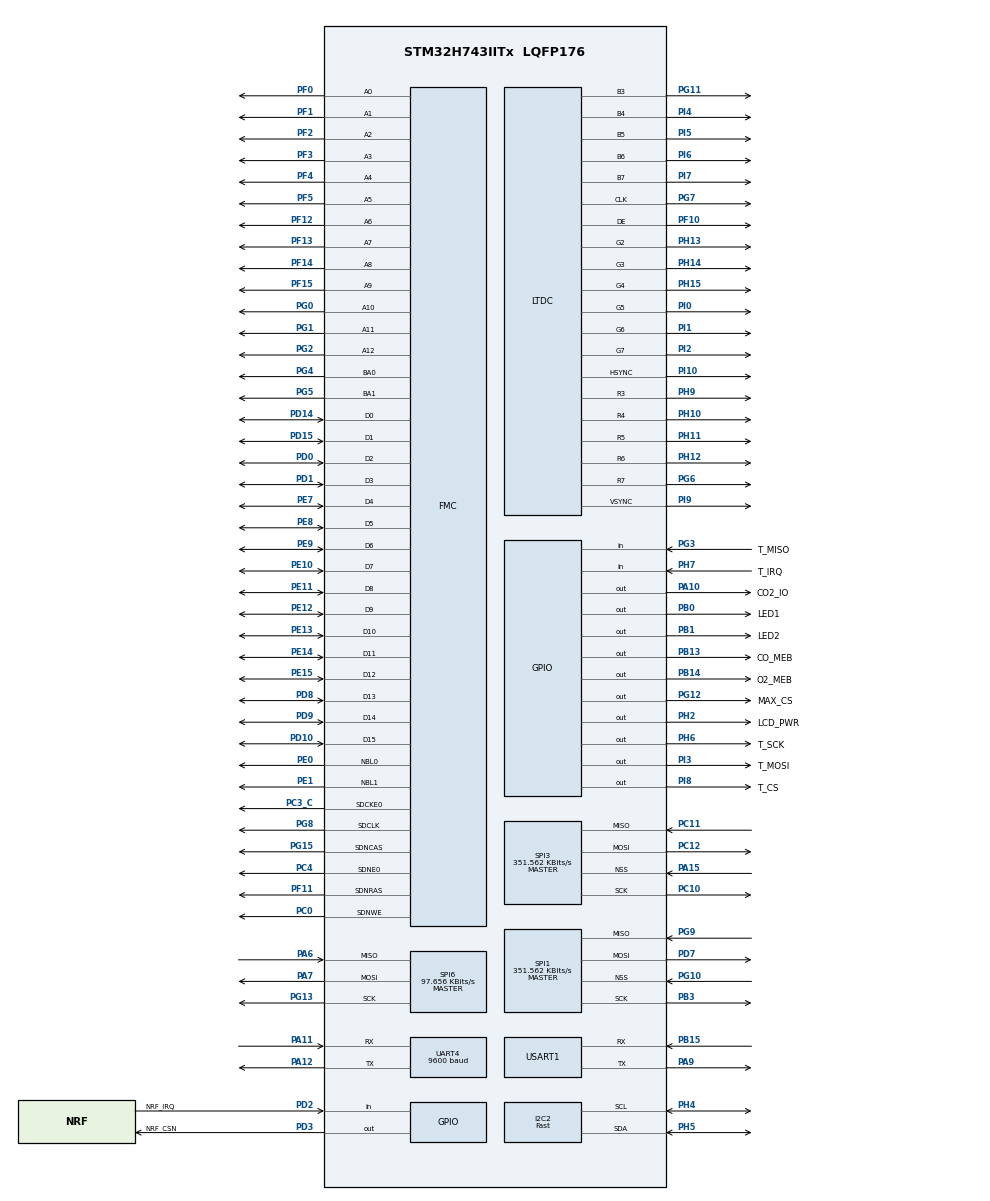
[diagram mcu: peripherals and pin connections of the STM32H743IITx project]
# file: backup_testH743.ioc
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CORTEX_M7.AccessPermission_Spec=MPU_REGION_FULL_ACCESS
CORTEX_M7.BaseAddress_Spec=0x24000000
CORTEX_M7.CPU_DCache=Enabled
CORTEX_M7.CPU_ICache=Enabled
CORTEX_M7.IsBufferable_Spec=MPU_ACCESS_BUFFERABLE
CORTEX_M7.IsCacheable_Spec=MPU_ACCESS_CACHEABLE
CORTEX_M7.IsShareable_Spec=MPU_ACCESS_NOT_SHAREABLE
CORTEX_M7.MPU_Control=MPU_PRIVILEGED_DEFAULT
CORTEX_M7.Size_Spec=MPU_REGION_SIZE_512KB
CORTEX_M7.SubRegionDisable_Spec=0x0
CORTEX_M7.default_mode_Activation=1
DMA2D.ColorMode=DMA2D_OUTPUT_RGB565
Dma.I2C2_RX.0.Direction=DMA_PERIPH_TO_MEMORY
Dma.I2C2_RX.0.EventEnable=DISABLE
Dma.I2C2_RX.0.FIFOMode=DMA_FIFOMODE_DISABLE
Dma.I2C2_RX.0.Instance=DMA1_Stream0
Dma.I2C2_RX.0.MemDataAlignment=DMA_MDATAALIGN_BYTE
Dma.I2C2_RX.0.MemInc=DMA_MINC_ENABLE
Dma.I2C2_RX.0.Mode=DMA_NORMAL
Dma.I2C2_RX.0.PeriphDataAlignment=DMA_PDATAALIGN_BYTE
Dma.I2C2_RX.0.PeriphInc=DMA_PINC_DISABLE
Dma.I2C2_RX.0.Polarity=HAL_DMAMUX_REQ_GEN_RISING
Dma.I2C2_RX.0.Priority=DMA_PRIORITY_LOW
Dma.I2C2_RX.0.RequestNumber=1
Dma.I2C2_RX.0.SignalID=NONE
Dma.I2C2_RX.0.SyncEnable=DISABLE
Dma.I2C2_RX.0.SyncPolarity=HAL_DMAMUX_SYNC_NO_EVENT
Dma.I2C2_RX.0.SyncRequestNumber=1
Dma.I2C2_RX.0.SyncSignalID=NONE
Dma.Request0=I2C2_RX
Dma.Request1=UART4_RX
Dma.UART4_RX.1.Direction=DMA_PERIPH_TO_MEMORY
Dma.UART4_RX.1.EventEnable=DISABLE
Dma.UART4_RX.1.FIFOMode=DMA_FIFOMODE_DISABLE
Dma.UART4_RX.1.Instance=DMA1_Stream1
Dma.UART4_RX.1.MemDataAlignment=DMA_MDATAALIGN_BYTE
Dma.UART4_RX.1.MemInc=DMA_MINC_ENABLE
Dma.UART4_RX.1.Mode=DMA_NORMAL
Dma.UART4_RX.1.PeriphDataAlignment=DMA_PDATAALIGN_BYTE
Dma.UART4_RX.1.PeriphInc=DMA_PINC_DISABLE
Dma.UART4_RX.1.Polarity=HAL_DMAMUX_REQ_GEN_RISING
Dma.UART4_RX.1.Priority=DMA_PRIORITY_LOW
Dma.UART4_RX.1.RequestNumber=1
Dma.UART4_RX.1.SignalID=NONE
Dma.UART4_RX.1.SyncEnable=DISABLE
Dma.UART4_RX.1.SyncPolarity=HAL_DMAMUX_SYNC_NO_EVENT
Dma.UART4_RX.1.SyncRequestNumber=1
Dma.UART4_RX.1.SyncSignalID=NONE
FMC.CASLatency1=FMC_SDRAM_CAS_LATENCY_3
FMC.ColumnBitsNumber1=FMC_SDRAM_COLUMN_BITS_NUM_9
FMC.ExitSelfRefreshDelay1=7
FMC.LoadToActiveDelay1=2
FMC.RCDDelay1=2
FMC.RPDelay1=2
FMC.RPDelay2=2
FMC.ReadBurst1=FMC_SDRAM_RBURST_ENABLE
FMC.ReadBurst2=FMC_SDRAM_RBURST_ENABLE
FMC.ReadPipeDelay1=FMC_SDRAM_RPIPE_DELAY_1
FMC.ReadPipeDelay2=FMC_SDRAM_RPIPE_DELAY_1
FMC.RowCycleDelay1=7
FMC.RowCycleDelay2=7
FMC.SDClockPeriod1=FMC_SDRAM_CLOCK_PERIOD_2
FMC.SDClockPeriod2=FMC_SDRAM_CLOCK_PERIOD_2
FMC.SelfRefreshTime1=5
FMC.WriteRecoveryTime1=4
FREERTOS.Mutexes01=sensorDataMutex,Dynamic,NULL,Available
FREERTOS.Tasks01=ControlTask,24,512,StartControlTask,Default,NULL,Dynamic,NULL,NULL;GUI_Task,40,8192,TouchGFX_Task,As external,NULL,Dynamic,NULL,NULL;SensorTask_I2C,24,512,StartSensorTask_I2C,Default,NULL,Dynamic,NULL,NULL;SensorTask_UART,24,512,StartSensorTask_UART,Default,NULL,Dynamic,NULL,NULL;SensorTask_SPI,24,512,StartSensorTask_SPI,Default,NULL,Dynamic,NULL,NULL;CommTask_NRT_SD,8,1536,StartCommTask_NRF_SD,Default,NULL,Dynamic,NULL,NULL
FREERTOS.configENABLE_FPU=1
FREERTOS.configTOTAL_HEAP_SIZE=65536
FREERTOS.configUSE_NEWLIB_REENTRANT=1
I2C2.I2C_Speed_Mode=I2C_Fast
I2C2.Timing=0x009034B6
LTDC.ActiveH=272
LTDC.ActiveW=480
LTDC.Alpha0_L0=0
LTDC.Alpha_L0=255
LTDC.FBStartAdress_L0=0xC0000000
LTDC.HBP=2
LTDC.HFP=2
LTDC.HSync=41
LTDC.ImageHeight_L0=272
LTDC.ImageWidth_L0=480
LTDC.Layers=0
LTDC.PixelFormat_L0=LTDC_PIXEL_FORMAT_RGB565
LTDC.VBP=2
LTDC.VFP=2
LTDC.VSync=10
LTDC.WindowX1_L0=480
LTDC.WindowY1_L0=272
Mcu.Family=STM32H7
Mcu.Name=STM32H743IITx
Mcu.Package=LQFP176
NVIC.DMA1_Stream0_IRQn=true\:5\:0\:false\:false\:true\:true\:false\:true\:true
NVIC.DMA1_Stream1_IRQn=true\:5\:0\:false\:false\:true\:true\:false\:true\:true
NVIC.DMA2D_IRQn=true\:6\:0\:true\:false\:true\:true\:true\:true\:true
NVIC.LTDC_ER_IRQn=true\:6\:0\:true\:false\:true\:true\:true\:true\:true
NVIC.LTDC_IRQn=true\:6\:0\:true\:false\:true\:true\:true\:true\:true
NVIC.PriorityGroup=NVIC_PRIORITYGROUP_4
NVIC.TIM6_DAC_IRQn=true\:15\:0\:false\:false\:true\:false\:false\:true\:true
NVIC.TimeBase=TIM6_DAC_IRQn
NVIC.TimeBaseIP=TIM6
PA10.GPIO_Label=CO2_IO
PA10.PinState=GPIO_PIN_SET
PA10.Signal=GPIO_Output
PA11.Mode=Asynchronous
PA11.Signal=UART4_RX
PA12.Mode=Asynchronous
PA12.Signal=UART4_TX
PA13\ (JTMS/SWDIO).Mode=Serial_Wire
PA13\ (JTMS/SWDIO).Signal=DEBUG_JTMS-SWDIO
PA14\ (JTCK/SWCLK).Mode=Serial_Wire
PA14\ (JTCK/SWCLK).Signal=DEBUG_JTCK-SWCLK
PA15\ (JTDI).Mode=NSS_Signal_Hard_Input
PA15\ (JTDI).Signal=SPI3_NSS
PA6.Mode=Full_Duplex_Master
PA6.Signal=SPI6_MISO
PA7.Mode=Full_Duplex_Master
PA7.Signal=SPI6_MOSI
PA9.Mode=Asynchronous
PA9.Signal=USART1_TX
PB0.GPIO_Label=LED1
PB0.Signal=GPIO_Output
PB1.GPIO_Label=LED2
PB1.Signal=GPIO_Output
PB13.GPIO_Label=CO_MEB
PB13.PinState=GPIO_PIN_SET
PB13.Signal=GPIO_Output
PB14.GPIO_Label=O2_MEB
PB14.PinState=GPIO_PIN_SET
PB14.Signal=GPIO_Output
PB15.Mode=Asynchronous
PB15.Signal=USART1_RX
PB3\ (JTDO/TRACESWO).Mode=Full_Duplex_Master
PB3\ (JTDO/TRACESWO).Signal=SPI1_SCK
PC0.Signal=FMC_SDNWE
PC10.Mode=Full_Duplex_Master
PC10.Signal=SPI3_SCK
PC11.Mode=Full_Duplex_Master
PC11.Signal=SPI3_MISO
PC12.Mode=Full_Duplex_Master
PC12.Signal=SPI3_MOSI
PC14-OSC32_IN\ (OSC32_IN).Mode=LSE-External-Oscillator
PC14-OSC32_IN\ (OSC32_IN).Signal=RCC_OSC32_IN
PC15-OSC32_OUT\ (OSC32_OUT).Mode=LSE-External-Oscillator
PC15-OSC32_OUT\ (OSC32_OUT).Signal=RCC_OSC32_OUT
PC3_C.Mode=SdramChipSelect1_1
PC3_C.Signal=FMC_SDCKE0
PC4.Mode=SdramChipSelect1_1
PC4.Signal=FMC_SDNE0
PD0.Signal=FMC_D2_DA2
PD1.Signal=FMC_D3_DA3
PD10.Signal=FMC_D15_DA15
PD14.Signal=FMC_D0_DA0
PD15.Signal=FMC_D1_DA1
PD2.GPIO_Label=NRF_IRQ
PD2.Signal=GPIO_Input
PD3.GPIO_Label=NRF_CSN
PD3.Signal=GPIO_Output
PD7.Mode=Full_Duplex_Master
PD7.Signal=SPI1_MOSI
PD8.Signal=FMC_D13_DA13
PD9.Signal=FMC_D14_DA14
PE0.Signal=FMC_NBL0
PE1.Signal=FMC_NBL1
PE10.Signal=FMC_D7_DA7
PE11.Signal=FMC_D8_DA8
PE12.Signal=FMC_D9_DA9
PE13.Signal=FMC_D10_DA10
PE14.Signal=FMC_D11_DA11
PE15.Signal=FMC_D12_DA12
PE7.Signal=FMC_D4_DA4
PE8.Signal=FMC_D5_DA5
PE9.Signal=FMC_D6_DA6
PF0.Signal=FMC_A0
PF1.Signal=FMC_A1
PF10.Mode=RGB565
PF10.Signal=LTDC_DE
PF11.Signal=FMC_SDNRAS
PF12.Signal=FMC_A6
PF13.Signal=FMC_A7
PF14.Signal=FMC_A8
PF15.Signal=FMC_A9
PF2.Signal=FMC_A2
PF3.Signal=FMC_A3
PF4.Signal=FMC_A4
PF5.Signal=FMC_A5
PG0.Signal=FMC_A10
PG1.Signal=FMC_A11
PG10.Mode=NSS_Signal_Hard_Input
PG10.Signal=SPI1_NSS
PG11.Mode=RGB565
PG11.Signal=LTDC_B3
PG12.GPIO_Label=MAX_CS
PG12.Signal=GPIO_Output
PG13.Mode=Full_Duplex_Master
PG13.Signal=SPI6_SCK
PG15.Signal=FMC_SDNCAS
PG2.Signal=FMC_A12
PG3.GPIO_Label=T_MISO
PG3.Signal=GPIO_Input
PG4.Signal=FMC_A14_BA0
PG5.Signal=FMC_A15_BA1
PG6.Mode=RGB565
PG6.Signal=LTDC_R7
PG7.Mode=RGB565
PG7.Signal=LTDC_CLK
PG8.Signal=FMC_SDCLK
PG9.Mode=Full_Duplex_Master
PG9.Signal=SPI1_MISO
PH0-OSC_IN\ (PH0).Mode=HSE-External-Oscillator
PH0-OSC_IN\ (PH0).Signal=RCC_OSC_IN
PH1-OSC_OUT\ (PH1).Mode=HSE-External-Oscillator
PH1-OSC_OUT\ (PH1).Signal=RCC_OSC_OUT
PH10.Mode=RGB565
PH10.Signal=LTDC_R4
PH11.Mode=RGB565
PH11.Signal=LTDC_R5
PH12.Mode=RGB565
PH12.Signal=LTDC_R6
PH13.Mode=RGB565
PH13.Signal=LTDC_G2
PH14.Mode=RGB565
PH14.Signal=LTDC_G3
PH15.Mode=RGB565
PH15.Signal=LTDC_G4
PH2.GPIO_Label=LCD_PWR
PH2.PinState=GPIO_PIN_SET
PH2.Signal=GPIO_Output
PH4.Mode=I2C
PH4.Signal=I2C2_SCL
PH5.Mode=I2C
PH5.Signal=I2C2_SDA
PH6.GPIO_Label=T_SCK
PH6.Signal=GPIO_Output
PH7.GPIO_Label=T_IRQ
PH7.GPIO_PuPd=GPIO_NOPULL
PH7.Signal=GPIO_Input
PH9.Mode=RGB565
PH9.Signal=LTDC_R3
PI0.Mode=RGB565
PI0.Signal=LTDC_G5
PI1.Mode=RGB565
PI1.Signal=LTDC_G6
PI10.Mode=RGB565
PI10.Signal=LTDC_HSYNC
PI2.Mode=RGB565
PI2.Signal=LTDC_G7
PI3.GPIO_Label=T_MOSI
PI3.Signal=GPIO_Output
PI4.Mode=RGB565
PI4.Signal=LTDC_B4
PI5.Mode=RGB565
PI5.Signal=LTDC_B5
PI6.Mode=RGB565
PI6.Signal=LTDC_B6
PI7.Mode=RGB565
PI7.Signal=LTDC_B7
PI8.GPIO_Label=T_CS
PI8.Signal=GPIO_Output
PI9.Mode=RGB565
PI9.Signal=LTDC_VSYNC
ProjectManager.HeapSize=0x1000
ProjectManager.StackSize=0x1000
ProjectManager.TargetToolchain=STM32CubeIDE
RCC.ADCCLockSelection=RCC_ADCCLKSOURCE_CLKP
RCC.ADCFreq_Value=64000000
RCC.APB1Freq_Value=100000000
RCC.APB2Freq_Value=100000000
RCC.APB3Freq_Value=100000000
RCC.APB4Freq_Value=100000000
RCC.CortexFreq_Value=400000000
RCC.D1PPRE=RCC_APB3_DIV2
RCC.D2PPRE1=RCC_APB1_DIV2
RCC.D2PPRE2=RCC_APB2_DIV2
RCC.D3PPRE=RCC_APB4_DIV2
RCC.DIVM1=2
RCC.DIVM2=25
RCC.DIVM3=5
RCC.DIVN1=64
RCC.DIVN2=360
RCC.DIVN3=36
RCC.DIVR2=3
RCC.DIVR3=20
RCC.FMCCLockSelection=RCC_FMCCLKSOURCE_PLL2
RCC.HCLKFreq_Value=200000000
RCC.HPRE=RCC_HCLK_DIV2
RCC.LockedElements=D1CPREOutput,AHBOutput,LTDCOutput,FMCoutput,CpuClockOutput,CortexSysOutput
RCC.PLL2FRACN=0
RCC.PLL3FRACN=0
RCC.PLLFRACN=0
RCC.PLLSourceVirtual=RCC_PLLSOURCE_HSE
RCC.PWR_Regulator_Voltage_Scale=PWR_REGULATOR_VOLTAGE_SCALE0
RCC.SPI123CLockSelection=RCC_SPI123CLKSOURCE_PLL3
RCC.SPI6CLockSelection=RCC_SPI6CLKSOURCE_HSE
RCC.SYSCLKFreq_VALUE=400000000
RCC.SYSCLKSource=RCC_SYSCLKSOURCE_PLLCLK
RCC.USBFreq_Value=400000000
RTC.Month=RTC_MONTH_APRIL
RTC.WeekDay=RTC_WEEKDAY_SATURDAY
SH.FMC_A0.0=FMC_A0,13b-sda1
SH.FMC_A1.0=FMC_A1,13b-sda1
SH.FMC_A10.0=FMC_A10,13b-sda1
SH.FMC_A11.0=FMC_A11,13b-sda1
SH.FMC_A12.0=FMC_A12,13b-sda1
SH.FMC_A14_BA0.0=FMC_BA0,FourSdramBanks1
SH.FMC_A15_BA1.0=FMC_BA1,FourSdramBanks1
SH.FMC_A2.0=FMC_A2,13b-sda1
SH.FMC_A3.0=FMC_A3,13b-sda1
SH.FMC_A4.0=FMC_A4,13b-sda1
SH.FMC_A5.0=FMC_A5,13b-sda1
SH.FMC_A6.0=FMC_A6,13b-sda1
SH.FMC_A7.0=FMC_A7,13b-sda1
SH.FMC_A8.0=FMC_A8,13b-sda1
SH.FMC_A9.0=FMC_A9,13b-sda1
SH.FMC_D0_DA0.0=FMC_D0,sd-16b-d1
SH.FMC_D10_DA10.0=FMC_D10,sd-16b-d1
SH.FMC_D11_DA11.0=FMC_D11,sd-16b-d1
SH.FMC_D12_DA12.0=FMC_D12,sd-16b-d1
SH.FMC_D13_DA13.0=FMC_D13,sd-16b-d1
SH.FMC_D14_DA14.0=FMC_D14,sd-16b-d1
SH.FMC_D15_DA15.0=FMC_D15,sd-16b-d1
SH.FMC_D1_DA1.0=FMC_D1,sd-16b-d1
SH.FMC_D2_DA2.0=FMC_D2,sd-16b-d1
SH.FMC_D3_DA3.0=FMC_D3,sd-16b-d1
SH.FMC_D4_DA4.0=FMC_D4,sd-16b-d1
SH.FMC_D5_DA5.0=FMC_D5,sd-16b-d1
SH.FMC_D6_DA6.0=FMC_D6,sd-16b-d1
SH.FMC_D7_DA7.0=FMC_D7,sd-16b-d1
SH.FMC_D8_DA8.0=FMC_D8,sd-16b-d1
SH.FMC_D9_DA9.0=FMC_D9,sd-16b-d1
SH.FMC_NBL0.0=FMC_NBL0,Sd2ByteEnable1
SH.FMC_NBL1.0=FMC_NBL1,Sd2ByteEnable1
SH.FMC_SDCLK.0=FMC_SDCLK,13b-sda1
SH.FMC_SDNCAS.0=FMC_SDNCAS,13b-sda1
SH.FMC_SDNRAS.0=FMC_SDNRAS,13b-sda1
SH.FMC_SDNWE.0=FMC_SDNWE,13b-sda1
SPI1.BaudRatePrescaler=SPI_BAUDRATEPRESCALER_256
SPI1.CalculateBaudRate=351.562 KBits/s
SPI1.Direction=SPI_DIRECTION_2LINES
SPI1.Mode=SPI_MODE_MASTER
SPI1.VirtualNSS=VM_NSSHARD
SPI1.VirtualType=VM_MASTER
SPI3.BaudRatePrescaler=SPI_BAUDRATEPRESCALER_256
SPI3.CalculateBaudRate=351.562 KBits/s
SPI3.Direction=SPI_DIRECTION_2LINES
SPI3.Mode=SPI_MODE_MASTER
SPI3.VirtualNSS=VM_NSSHARD
SPI3.VirtualType=VM_MASTER
SPI6.BaudRatePrescaler=SPI_BAUDRATEPRESCALER_256
SPI6.CalculateBaudRate=97.656 KBits/s
SPI6.Direction=SPI_DIRECTION_2LINES
SPI6.Mode=SPI_MODE_MASTER
SPI6.VirtualType=VM_MASTER
STMicroelectronics.X-CUBE-TOUCHGFX.4.26.0.ApplicationCcGraphicsJjApplication=TouchGFXOoGenerator
STMicroelectronics.X-CUBE-TOUCHGFX.4.26.0.tgfx_address1=0xC0000000
STMicroelectronics.X-CUBE-TOUCHGFX.4.26.0.tgfx_address2=0xC0170000
STMicroelectronics.X-CUBE-TOUCHGFX.4.26.0.tgfx_buffering_strategy=Single
STMicroelectronics.X-CUBE-TOUCHGFX.4.26.0.tgfx_display_interface=disp_ltdc
STMicroelectronics.X-CUBE-TOUCHGFX.4.26.0.tgfx_framebuffer_stride=Disabled
STMicroelectronics.X-CUBE-TOUCHGFX.4.26.0.tgfx_hardware_accelerator=dma_2d
STMicroelectronics.X-CUBE-TOUCHGFX.4.26.0.tgfx_location=By Address
STMicroelectronics.X-CUBE-TOUCHGFX.4.26.0.tgfx_vector_fonts=Enabled
STMicroelectronics.X-CUBE-TOUCHGFX.4.26.0.tgfx_vector_rendering=Software
STMicroelectronics.X-CUBE-TOUCHGFX.4.26.0.tgfx_vsync=vsync_ltdc
STMicroelectronics.X-CUBE-TOUCHGFX.4.26.0_IsPackSelfContextualization=true
UART4.BaudRate=9600
USART1.VirtualMode-Asynchronous=VM_ASYNC
VP_CRC_VS_CRC.Mode=CRC_Activate
VP_DMA2D_VS_DMA2D.Mode=DMA2D_Activate
VP_FREERTOS_VS_CMSIS_V2.Mode=CMSIS_V2
VP_MEMORYMAP_VS_MEMORYMAP.Mode=CurAppReg
VP_RTC_VS_RTC_Activate.Mode=RTC_Enabled
VP_RTC_VS_RTC_Calendar.Mode=RTC_Calendar
VP_STMicroelectronics.X-CUBE-TOUCHGFX_VS_GraphicsJjApplication_4.26.0.Mode=GraphicsJjApplication
VP_SYS_VS_tim6.Mode=TIM6
board=custom

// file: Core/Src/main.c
/* USER CODE BEGIN Header */
/**
  ******************************************************************************
  * @file           : main.c
  * @brief          : Main program body
  ******************************************************************************
  * @attention
  *
  * Copyright (c) 2025 STMicroelectronics.
  * All rights reserved.
  *
  * This software is licensed under terms that can be found in the LICENSE file
  * in the root directory of this software component.
  * If no LICENSE file comes with this software, it is provided AS-IS.
  *
  ******************************************************************************
  */
/* USER CODE END Header */
#include "main.h"
#include "cmsis_os.h"
#include "crc.h"
#include "dma.h"
#include "dma2d.h"
#include "i2c.h"
#include "ltdc.h"
#include "rtc.h"
#include "spi.h"
#include "usart.h"
#include "gpio.h"
#include "fmc.h"
#include "app_touchgfx.h"
#include "Max66.h"
/* USER CODE BEGIN Includes */
#include "FreeRTOS.h"
#include "semphr.h"

#include "config.h"

#include "k33.h"
#include "LMP91000.h"

/* USER CODE END Includes */

/* USER CODE BEGIN PTD */
/*
#define CO_MEMORY_ENABLE		  HAL_GPIO_WritePin(CO_MEB_GPIO_Port,CO_MEB_Pin,GPIO_PIN_RESET)
#define CO_MEMORY_DISABLE		  HAL_GPIO_WritePin(CO_MEB_GPIO_Port,CO_MEB_Pin,GPIO_PIN_SET)

////////////////////////////////////

#define O2_MEMORY_ENABLE		  HAL_GPIO_WritePin(O2_MEB_GPIO_Port,O2_MEB_Pin,GPIO_PIN_RESET)
#define O2_MEMORY_DISABLE		  HAL_GPIO_WritePin(O2_MEB_GPIO_Port,O2_MEB_Pin,GPIO_PIN_SET)

uint8_t co_data[2];
uint8_t o2_data[2];

*/
/* USER CODE END PTD */

/* USER CODE BEGIN PM */
extern I2C_HandleTypeDef hi2c2;
/* USER CODE END PM */

/* USER CODE BEGIN PV */

void MPU_Config_SDRAM(void)
{
    MPU_Region_InitTypeDef MPU_InitStruct;

    /* Disable MPU */
    HAL_MPU_Disable();

    /* Configure SDRAM region: 16MB at 0xC0000000, cacheable, full access, XN */
    MPU_InitStruct.Enable           = MPU_REGION_ENABLE;
    MPU_InitStruct.BaseAddress      = 0xC0000000;
    MPU_InitStruct.Size             = MPU_REGION_SIZE_16MB;
    MPU_InitStruct.AccessPermission = MPU_REGION_FULL_ACCESS;
    MPU_InitStruct.IsBufferable     = MPU_ACCESS_NOT_BUFFERABLE;
    MPU_InitStruct.IsCacheable      = MPU_ACCESS_CACHEABLE;      // IMPORTANT
    MPU_InitStruct.IsShareable      = MPU_ACCESS_NOT_SHAREABLE;
    MPU_InitStruct.Number           = MPU_REGION_NUMBER0;       // use an unused region number
    MPU_InitStruct.TypeExtField     = MPU_TEX_LEVEL0;
    MPU_InitStruct.SubRegionDisable = 0x00;
    MPU_InitStruct.DisableExec      = MPU_INSTRUCTION_ACCESS_DISABLE; // no exec

    HAL_MPU_ConfigRegion(&MPU_InitStruct);

    /* Re-enable MPU with default memory map for privileged accesses */
    HAL_MPU_Enable(MPU_PRIVILEGED_DEFAULT);
}
/* USER CODE END PV */

void SystemClock_Config(void);
void PeriphCommonClock_Config(void);
static void MPU_Config(void);
void MX_FREERTOS_Init(void);
/* USER CODE BEGIN PFP */
typedef struct
{
    float slope;
    float intercept;
} LineParams_t;

typedef struct
{
    LineParams_t co2;
    LineParams_t co;
    LineParams_t o2;
    uint8_t valid;
} CalibrationCache_t;
/* USER CODE END PFP */

/* USER CODE BEGIN 0 */

K33_HandleTypeDef k33;
uint16_t rawCO,rawO2 ;

	bool Logger_State;
	bool NRF_State;
/* USER CODE END 0 */

int main(void)
{

  /* MPU Configuration--------------------------------------------------------*/
  MPU_Config();

  /* Enable the CPU Cache */

  /* Enable I-Cache---------------------------------------------------------*/
  SCB_EnableICache();

  /* Enable D-Cache---------------------------------------------------------*/
 SCB_EnableDCache();
  /* MCU Configuration--------------------------------------------------------*/

  /* Reset of all peripherals, Initializes the Flash interface and the Systick. */
  HAL_Init();

  /* Configure the system clock */
  SystemClock_Config();

  /* Configure the peripherals common clocks */
  PeriphCommonClock_Config();

  /* Initialize all configured peripherals */
  MX_GPIO_Init();
  MX_DMA_Init();
  MX_DMA2D_Init();
  MX_FMC_Init();
  MX_LTDC_Init();
  MX_CRC_Init();
  MX_RTC_Init();
  MX_UART4_Init();
  MX_USART1_UART_Init();
  MX_I2C2_Init();
  MX_SPI1_Init();
  MX_SPI3_Init();
  MX_SPI6_Init();
  MX_TouchGFX_Init();
  /* Call PreOsInit function */
  MX_TouchGFX_PreOSInit();
  /* USER CODE BEGIN 2 */
  DWT_Delay_Init();

/*
	O2_MEMORY_DISABLE;
 	HAL_Delay(1000);

	CO_MEMORY_ENABLE;
	HAL_Delay(1000);
	///////////////////////
	co_data[0] = TI_LMP91000_LOCK_REG;
	co_data[1] = 0x00;
	HAL_I2C_Master_Transmit(&hi2c2, LMP91000_I2C_Address, co_data, 2, 50);

	// Configure TIA
	co_data[0] = TI_LMP91000_TIACN_REG;
	co_data[1] = 0x18; // 7kOhm, 10Ohm load
	HAL_I2C_Master_Transmit(&hi2c2, LMP91000_I2C_Address, co_data, 2, 50);

	// Configure Reference
	co_data[0] = TI_LMP91000_REFCN_REG;
	co_data[1] = 0x10; // Internal zero 20%, Bias 0%
	HAL_I2C_Master_Transmit(&hi2c2, LMP91000_I2C_Address, co_data, 2, 50);

	// Set Mode
	co_data[0] = TI_LMP91000_MODECN_REG;
	co_data[1] = 0x03; // 3-lead mode
	HAL_I2C_Master_Transmit(&hi2c2, LMP91000_I2C_Address, co_data, 2, 50);

	// Lock registers (optional)
	co_data[0] = TI_LMP91000_LOCK_REG;
	co_data[1] = 0x01;
	HAL_I2C_Master_Transmit(&hi2c2, LMP91000_I2C_Address, co_data, 2, 50);
	/////////////////////
	CO_MEMORY_DISABLE;

 	HAL_Delay(1000);

	O2_MEMORY_ENABLE;
	HAL_Delay(2000);

	o2_data[0] = TI_LMP91000_LOCK_REG;
	o2_data[1] = 0x00;
	HAL_I2C_Master_Transmit(&hi2c2, LMP91000_I2C_Address, o2_data, 2, 50);

	o2_data[0] = TI_LMP91000_TIACN_REG;
	o2_data[1] = 0b00000101; // 2.75kΩ, 10Ω
	HAL_I2C_Master_Transmit(&hi2c2, LMP91000_I2C_Address, o2_data, 2, 50);

	o2_data[0] = TI_LMP91000_REFCN_REG;
	o2_data[1] = 0b01010000; // Bias +10%, Internal zero 20%
	HAL_I2C_Master_Transmit(&hi2c2, LMP91000_I2C_Address, o2_data, 2, 50);

	o2_data[0] = TI_LMP91000_MODECN_REG;
	o2_data[1] = 0x03; // 3-lead amperometric cell
	HAL_I2C_Master_Transmit(&hi2c2, LMP91000_I2C_Address, o2_data, 2, 50);

	o2_data[0] = TI_LMP91000_LOCK_REG;
	o2_data[1] = 0x01;
	HAL_I2C_Master_Transmit(&hi2c2, LMP91000_I2C_Address, o2_data, 2, 50);

	O2_MEMORY_DISABLE;
*/

  /* USER CODE END 2 */

  /* Init scheduler */
  osKernelInitialize();  /* Call init function for freertos objects (in cmsis_os2.c) */
  MX_FREERTOS_Init();

  /* Start scheduler */
  osKernelStart();

  /* We should never get here as control is now taken by the scheduler */

  /* Infinite loop */
  while (1)
  {

  }
}

void SystemClock_Config(void)
{
  RCC_OscInitTypeDef RCC_OscInitStruct = {0};
  RCC_ClkInitTypeDef RCC_ClkInitStruct = {0};

  /** Supply configuration update enable
  */
  HAL_PWREx_ConfigSupply(PWR_LDO_SUPPLY);

  /** Configure the main internal regulator output voltage
  */
  __HAL_PWR_VOLTAGESCALING_CONFIG(PWR_REGULATOR_VOLTAGE_SCALE0);

  while(!__HAL_PWR_GET_FLAG(PWR_FLAG_VOSRDY)) {}

  /** Initializes the RCC Oscillators according to the specified parameters
  * in the RCC_OscInitTypeDef structure.
  */
  RCC_OscInitStruct.OscillatorType = RCC_OSCILLATORTYPE_LSI|RCC_OSCILLATORTYPE_HSE;
  RCC_OscInitStruct.HSEState = RCC_HSE_ON;
  RCC_OscInitStruct.LSIState = RCC_LSI_ON;
  RCC_OscInitStruct.PLL.PLLState = RCC_PLL_ON;
  RCC_OscInitStruct.PLL.PLLSource = RCC_PLLSOURCE_HSE;
  RCC_OscInitStruct.PLL.PLLM = 2;
  RCC_OscInitStruct.PLL.PLLN = 64;
  RCC_OscInitStruct.PLL.PLLP = 2;
  RCC_OscInitStruct.PLL.PLLQ = 2;
  RCC_OscInitStruct.PLL.PLLR = 2;
  RCC_OscInitStruct.PLL.PLLRGE = RCC_PLL1VCIRANGE_3;
  RCC_OscInitStruct.PLL.PLLVCOSEL = RCC_PLL1VCOWIDE;
  RCC_OscInitStruct.PLL.PLLFRACN = 0;
  if (HAL_RCC_OscConfig(&RCC_OscInitStruct) != HAL_OK)
  {
    Error_Handler();
  }

  /** Initializes the CPU, AHB and APB buses clocks
  */
  RCC_ClkInitStruct.ClockType = RCC_CLOCKTYPE_HCLK|RCC_CLOCKTYPE_SYSCLK
                              |RCC_CLOCKTYPE_PCLK1|RCC_CLOCKTYPE_PCLK2
                              |RCC_CLOCKTYPE_D3PCLK1|RCC_CLOCKTYPE_D1PCLK1;
  RCC_ClkInitStruct.SYSCLKSource = RCC_SYSCLKSOURCE_PLLCLK;
  RCC_ClkInitStruct.SYSCLKDivider = RCC_SYSCLK_DIV1;
  RCC_ClkInitStruct.AHBCLKDivider = RCC_HCLK_DIV2;
  RCC_ClkInitStruct.APB3CLKDivider = RCC_APB3_DIV2;
  RCC_ClkInitStruct.APB1CLKDivider = RCC_APB1_DIV2;
  RCC_ClkInitStruct.APB2CLKDivider = RCC_APB2_DIV2;
  RCC_ClkInitStruct.APB4CLKDivider = RCC_APB4_DIV2;

  if (HAL_RCC_ClockConfig(&RCC_ClkInitStruct, FLASH_LATENCY_2) != HAL_OK)
  {
    Error_Handler();
  }
}

void PeriphCommonClock_Config(void)
{
  RCC_PeriphCLKInitTypeDef PeriphClkInitStruct = {0};

  /** Initializes the peripherals clock
  */
  PeriphClkInitStruct.PeriphClockSelection = RCC_PERIPHCLK_SPI3|RCC_PERIPHCLK_SPI1
                              |RCC_PERIPHCLK_LTDC;
  PeriphClkInitStruct.PLL3.PLL3M = 5;
  PeriphClkInitStruct.PLL3.PLL3N = 36;
  PeriphClkInitStruct.PLL3.PLL3P = 2;
  PeriphClkInitStruct.PLL3.PLL3Q = 2;
  PeriphClkInitStruct.PLL3.PLL3R = 20;
  PeriphClkInitStruct.PLL3.PLL3RGE = RCC_PLL3VCIRANGE_2;
  PeriphClkInitStruct.PLL3.PLL3VCOSEL = RCC_PLL3VCOMEDIUM;
  PeriphClkInitStruct.PLL3.PLL3FRACN = 0;
  PeriphClkInitStruct.Spi123ClockSelection = RCC_SPI123CLKSOURCE_PLL3;
  if (HAL_RCCEx_PeriphCLKConfig(&PeriphClkInitStruct) != HAL_OK)
  {
    Error_Handler();
  }
}

 /* MPU Configuration */

void MPU_Config(void)
{
  MPU_Region_InitTypeDef MPU_InitStruct = {0};

  /* Disables the MPU */
  HAL_MPU_Disable();

  /** Initializes and configures the Region and the memory to be protected
  */
  MPU_InitStruct.Enable = MPU_REGION_ENABLE;
  MPU_InitStruct.Number = MPU_REGION_NUMBER0;
  MPU_InitStruct.BaseAddress = 0x24000000;
  MPU_InitStruct.Size = MPU_REGION_SIZE_512KB;
  MPU_InitStruct.SubRegionDisable = 0x0;
  MPU_InitStruct.TypeExtField = MPU_TEX_LEVEL0;
  MPU_InitStruct.AccessPermission = MPU_REGION_FULL_ACCESS;
  MPU_InitStruct.DisableExec = MPU_INSTRUCTION_ACCESS_DISABLE;
  MPU_InitStruct.IsShareable = MPU_ACCESS_NOT_SHAREABLE;
  MPU_InitStruct.IsCacheable = MPU_ACCESS_CACHEABLE;
  MPU_InitStruct.IsBufferable = MPU_ACCESS_BUFFERABLE;

  HAL_MPU_ConfigRegion(&MPU_InitStruct);
  /* Enables the MPU */
  HAL_MPU_Enable(MPU_PRIVILEGED_DEFAULT);

}

void HAL_TIM_PeriodElapsedCallback(TIM_HandleTypeDef *htim)
{
  if (htim->Instance == TIM6)
  {
    HAL_IncTick();
  }
}

void Error_Handler(void)
{
  __disable_irq();
  while (1)
  {
  }
}

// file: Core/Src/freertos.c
/* USER CODE BEGIN Header */
/**
  ******************************************************************************
  * File Name          : freertos.c
  * Description        : Code for freertos applications
  ******************************************************************************
  * @attention
  *
  * Copyright (c) 2025 STMicroelectronics.
  * All rights reserved.
  *
  * This software is licensed under terms that can be found in the LICENSE file
  * in the root directory of this software component.
  * If no LICENSE file comes with this software, it is provided AS-IS.
  *
  ******************************************************************************
  */
/* USER CODE END Header */

#include "FreeRTOS.h"
#include "task.h"
#include "main.h"
#include "cmsis_os.h"

/* USER CODE BEGIN Includes */
#include "semphr.h"
#include <stdio.h>
#include "sensor_data.h"
#include "sht22.h"   /* make sure this header exists and declares SHT22_t and SHT22_Read / SHT22_Init */
#include "LMP91000.h"
//#include "k33.h"
#include "gas_sensor.h"
#include "gas_calibration.h"
#include "slope_offset_calib.h"
#include <string.h>
#include "ADS1015_ADS1115.h"
#include "Max66.h"

#include "ee_test.h"
#include "k33_config.h"
#include "k33_modbus.h"
#include "k33_sensor.h"
/* USER CODE END Includes */

/* USER CODE BEGIN PTD */
extern I2C_HandleTypeDef hi2c2;
//extern K33_HandleTypeDef k33;
extern UART_HandleTypeDef huart4;
extern UART_HandleTypeDef huart1;
extern SPI_HandleTypeDef hspi6;

extern uint16_t rawCO,rawO2 ;

/* USER CODE END PTD */

/* USER CODE BEGIN PD */
#define CO_MEMORY_ENABLE		  HAL_GPIO_WritePin(CO_MEB_GPIO_Port,CO_MEB_Pin,GPIO_PIN_RESET)
#define CO_MEMORY_DISABLE		  HAL_GPIO_WritePin(CO_MEB_GPIO_Port,CO_MEB_Pin,GPIO_PIN_SET)

////////////////////////////////////

#define O2_MEMORY_ENABLE		  HAL_GPIO_WritePin(O2_MEB_GPIO_Port,O2_MEB_Pin,GPIO_PIN_RESET)
#define O2_MEMORY_DISABLE		  HAL_GPIO_WritePin(O2_MEB_GPIO_Port,O2_MEB_Pin,GPIO_PIN_SET)

ThermoCouple sensor_th1;
	float Th1_temp = 0;
	int intpart;
	void InitThermocouple1(void) {
		sensor_th1.Thx_CS_Pin = MAX_CS_Pin;			// CS Pin
		sensor_th1.Thx_CS_Port = MAX_CS_GPIO_Port;	// CS GPIO PORT
		sensor_th1.hspi = &hspi6;						// SPI6
	}

uint8_t co_data[2];
uint8_t o2_data[2];

ADS1xx5_I2C ads;

/* USER CODE END PD */

/* USER CODE BEGIN PM */
LMP91000_Handle_t lmpCO =
{
    .hi2c      = &hi2c2,
    .menb_port = GPIOB,
    .menb_pin  = GPIO_PIN_13,   // CO MENB

    .tiacn =
        TI_LMP91000_TIA_GAIN_35_K_Ohm |
        TI_LMP91000_RLAOD_10_Ohm,

    .refcn =
        TI_LMP91000_INT_Z_50 |
        TI_LMP91000_BIAS_SIGN_POSITIVE |
        TI_LMP91000_BIAS_SELECTION_10_P,

    .modecn =
        TI_LMP91000_FET_SHORT_DISABLED |
        TI_LMP91000_OP_MODE_3_LEAD
};

LMP91000_Handle_t lmpO2 =
{
    .hi2c      = &hi2c2,
    .menb_port = GPIOB,
    .menb_pin  = GPIO_PIN_14,   // O2 MENB

    .tiacn =
        TI_LMP91000_TIA_GAIN_120_K_Ohm |
        TI_LMP91000_RLAOD_10_Ohm,

    .refcn =
        TI_LMP91000_INT_Z_O2_GROUDN_REFERRED |
        TI_LMP91000_BIAS_SELECTION_0_P,   // NO bias

    .modecn =
        TI_LMP91000_FET_SHORT_DISABLED |
        TI_LMP91000_OP_MODE_3_LEAD
};
/* USER CODE END PM */

/* Definitions for ControlTask */
osThreadId_t ControlTaskHandle;
const osThreadAttr_t ControlTask_attributes = {
  .name = "ControlTask",
  .stack_size = 512 * 4,
  .priority = (osPriority_t) osPriorityNormal,
};
/* Definitions for GUI_Task */
osThreadId_t GUI_TaskHandle;
const osThreadAttr_t GUI_Task_attributes = {
  .name = "GUI_Task",
  .stack_size = 8192 * 4,
  .priority = (osPriority_t) osPriorityHigh,
};
/* Definitions for SensorTask_I2C */
osThreadId_t SensorTask_I2CHandle;
const osThreadAttr_t SensorTask_I2C_attributes = {
  .name = "SensorTask_I2C",
  .stack_size = 512 * 4,
  .priority = (osPriority_t) osPriorityNormal,
};
/* Definitions for SensorTask_UART */
osThreadId_t SensorTask_UARTHandle;
const osThreadAttr_t SensorTask_UART_attributes = {
  .name = "SensorTask_UART",
  .stack_size = 512 * 4,
  .priority = (osPriority_t) osPriorityNormal,
};
/* Definitions for SensorTask_SPI */
osThreadId_t SensorTask_SPIHandle;
const osThreadAttr_t SensorTask_SPI_attributes = {
  .name = "SensorTask_SPI",
  .stack_size = 512 * 4,
  .priority = (osPriority_t) osPriorityNormal,
};
/* Definitions for CommTask_NRT_SD */
osThreadId_t CommTask_NRT_SDHandle;
const osThreadAttr_t CommTask_NRT_SD_attributes = {
  .name = "CommTask_NRT_SD",
  .stack_size = 1536 * 4,
  .priority = (osPriority_t) osPriorityLow,
};
/* Definitions for sensorDataMutex */
osMutexId_t sensorDataMutexHandle;
const osMutexAttr_t sensorDataMutex_attributes = {
  .name = "sensorDataMutex"
};

/* USER CODE BEGIN FunctionPrototypes */
osMutexId_t i2c2MutexHandle;
const osMutexAttr_t i2c2Mutex_attributes = {
    .name = "i2c2Mutex"
};

osMutexId_t i2cBusMutexHandle;
const osMutexAttr_t i2cBusMutex_attributes = {
  .name = "i2cBusMutex"
};

/* USER CODE END FunctionPrototypes */

void StartControlTask(void *argument);
extern void TouchGFX_Task(void *argument);
void StartSensorTask_I2C(void *argument);
void StartSensorTask_UART(void *argument);
void StartSensorTask_SPI(void *argument);
void StartCommTask_NRF_SD(void *argument);

void MX_FREERTOS_Init(void); /* (MISRA C 2004 rule 8.1) */

void MX_FREERTOS_Init(void) {
  /* Create the mutex(es) */
  /* creation of sensorDataMutex */

  /* USER CODE BEGIN RTOS_QUEUES */
  /* add queues, ... */

	  sensorDataMutexHandle = osMutexNew(&sensorDataMutex_attributes);
	  i2cBusMutexHandle = osMutexNew(&i2cBusMutex_attributes);

  /* USER CODE END RTOS_QUEUES */

  /* Create the thread(s) */
  /* creation of ControlTask */
  ControlTaskHandle = osThreadNew(StartControlTask, NULL, &ControlTask_attributes);

  /* creation of GUI_Task */
  GUI_TaskHandle = osThreadNew(TouchGFX_Task, NULL, &GUI_Task_attributes);

  /* creation of SensorTask_I2C */
  SensorTask_I2CHandle = osThreadNew(StartSensorTask_I2C, NULL, &SensorTask_I2C_attributes);

  /* creation of SensorTask_UART */
  SensorTask_UARTHandle = osThreadNew(StartSensorTask_UART, NULL, &SensorTask_UART_attributes);

  /* creation of SensorTask_SPI */
  SensorTask_SPIHandle = osThreadNew(StartSensorTask_SPI, NULL, &SensorTask_SPI_attributes);

  /* creation of CommTask_NRT_SD */
  CommTask_NRT_SDHandle = osThreadNew(StartCommTask_NRF_SD, NULL, &CommTask_NRT_SD_attributes);

}

void StartControlTask(void *argument)
{
  for(;;)
  {
	  osDelay(1);
  }
}

void StartSensorTask_I2C(void *argument)
{
  /* USER CODE BEGIN StartSensorTask_I2C */
  /* Infinite loop */

	/* -------- Init ONCE -------- */

	O2_MEMORY_DISABLE;
	osDelay(1000);

	CO_MEMORY_ENABLE;
	osDelay(1000);
	///////////////////////
	co_data[0] = TI_LMP91000_LOCK_REG;
	co_data[1] = 0x00;
	HAL_I2C_Master_Transmit(&hi2c2, LMP91000_I2C_Address, co_data, 2, 50);

	// Configure TIA
	co_data[0] = TI_LMP91000_TIACN_REG;
	co_data[1] = 0x18; // 7kOhm, 10Ohm load
	HAL_I2C_Master_Transmit(&hi2c2, LMP91000_I2C_Address, co_data, 2, 50);

	// Configure Reference
	co_data[0] = TI_LMP91000_REFCN_REG;
	co_data[1] = 0x10; // Internal zero 20%, Bias 0%
	HAL_I2C_Master_Transmit(&hi2c2, LMP91000_I2C_Address, co_data, 2, 50);

	// Set Mode
	co_data[0] = TI_LMP91000_MODECN_REG;
	co_data[1] = 0x03; // 3-lead mode
	HAL_I2C_Master_Transmit(&hi2c2, LMP91000_I2C_Address, co_data, 2, 50);

	// Lock registers (optional)
	co_data[0] = TI_LMP91000_LOCK_REG;
	co_data[1] = 0x01;
	HAL_I2C_Master_Transmit(&hi2c2, LMP91000_I2C_Address, co_data, 2, 50);
	/////////////////////
	CO_MEMORY_DISABLE;

	osDelay(1000);
	O2_MEMORY_ENABLE;
		osDelay(2000);

		o2_data[0] = TI_LMP91000_LOCK_REG;
		o2_data[1] = 0x00;
		HAL_I2C_Master_Transmit(&hi2c2, LMP91000_I2C_Address, o2_data, 2, 50);

		o2_data[0] = TI_LMP91000_TIACN_REG;
		o2_data[1] = 0b00000101; // 2.75kΩ, 10Ω
		HAL_I2C_Master_Transmit(&hi2c2, LMP91000_I2C_Address, o2_data, 2, 50);

		o2_data[0] = TI_LMP91000_REFCN_REG;
		o2_data[1] = 0b01010000; // Bias +10%, Internal zero 20%
		HAL_I2C_Master_Transmit(&hi2c2, LMP91000_I2C_Address, o2_data, 2, 50);

		o2_data[0] = TI_LMP91000_MODECN_REG;
		o2_data[1] = 0x03; // 3-lead amperometric cell
		HAL_I2C_Master_Transmit(&hi2c2, LMP91000_I2C_Address, o2_data, 2, 50);

		o2_data[0] = TI_LMP91000_LOCK_REG;
		o2_data[1] = 0x01;
		HAL_I2C_Master_Transmit(&hi2c2, LMP91000_I2C_Address, o2_data, 2, 50);

		O2_MEMORY_DISABLE;

	 extern osMutexId_t i2cBusMutexHandle;

        GasCalibration_Init();

        ADS1115(&ads, &hi2c2, ADS_ADDR_GND);

        SHT2x_Init(&hi2c2);
        SHT2x_SoftReset();
        osDelay(20);

        InitThermocouple1();
        char uart_buffer[100];
        float temp, hum;
        uint16_t ch0 = 0, ch1 = 0;

        float o2_pct , co_ppm ;

  for(;;)
  {

	  if (osMutexAcquire(sensorDataMutexHandle, 500) == osOK)
	  	  	      {

	  	  	        hum = SHT2x_GetRelativeHumidity(1);
	  	  	        temp = SHT2x_GetTemperature(1);

	  	  	        gSensorData.temperature = temp;
	  	  	        gSensorData.humidity    = hum;

			        osMutexRelease(sensorDataMutexHandle);
	  	  	      }

	    if (osMutexAcquire(i2cBusMutexHandle, pdMS_TO_TICKS(200)) == osOK) {
	            ch0 = ADSreadADC_SingleEnded(&ads, 0);
	            osDelay(20);
	            ch1 = ADSreadADC_SingleEnded(&ads, 1);
	            osMutexRelease(i2cBusMutexHandle);
	        }

	        if (osMutexAcquire(sensorDataMutexHandle, pdMS_TO_TICKS(50)) == osOK) {
	            gSensorData.rawCO  = ch0;
	            gSensorData.rawO2  = ch1;

	            co_ppm = CO_CalcPPM(gSensorData.rawCO);
	            o2_pct = O2_CalcPercent(gSensorData.rawO2);

	            gSensorData.co_ppm = co_ppm;
	            gSensorData.o2_percent = o2_pct;

	            g_co_x10  = (int16_t)(co_ppm  * 10.0f);
	            g_o2_x10  = (int16_t)(o2_pct  * 10.0f);

	            osMutexRelease(sensorDataMutexHandle);
	        }

	        if (osMutexAcquire(sensorDataMutexHandle, pdMS_TO_TICKS(200)) == osOK) {
	       		        ReadThermoCouple(&sensor_th1);
	       		       	  		if (sensor_th1.connected) {
	       		       	  			 gSensorData.probe_temp =sensor_th1.Thx_celcius;

	       		       	  		}else{

	       		       	  			gSensorData.probe_temp = 10.0f;
	       		       	  		}
	       			            osMutexRelease(sensorDataMutexHandle);

	       		        }

	  	  HAL_GPIO_TogglePin(LED1_GPIO_Port, LED1_Pin);

      /* -------- Proper sampling period -------- */
      osDelay(pdMS_TO_TICKS(500));   // 1 Hz (perfect)
      }
  /* USER CODE END StartSensorTask_I2C */
}

void StartSensorTask_UART(void *argument)
{
  /* USER CODE BEGIN StartSensorTask_UART */
  /* Infinite loop */

	K33_Modbus_Init(&huart4);
	K33_Sensor_Init();
	uint32_t s_co2StartTick = osKernelGetTickCount();

	    for (;;)
	    {
	        K33_CO2Reading_t co2_read;
	        K33_Status_t st = K33_ReadCO2(&co2_read);
	        if (st == K33_OK)
	        {
	            float co2_pct = CO2_CalcPercent(co2_read.value);

	            /* Startup hold: right after boot the cell is not flushed yet and the
	             * sensor reports an at/over-ceiling value (shown as 30%). Hide it as 0. */
	            if (((osKernelGetTickCount() - s_co2StartTick) < pdMS_TO_TICKS(K33_CO2_STARTUP_HOLD_MS)) &&
	                (co2_read.raw >= K33_CO2_RAW_MAX))
	            {
	                co2_read.raw = 0u;
	                co2_pct = 0.0f;
	            }

	            if (osMutexAcquire(sensorDataMutexHandle, pdMS_TO_TICKS(50)) == osOK)
	            {
	                gSensorData.rawCO2 = co2_read.raw;
	                gSensorData.co2_p = co2_pct;
	                gSensorData.co2_ppm = (uint16_t)(co2_pct * 10000.0f);
	                g_co2_x10 = (uint32_t)(gSensorData.co2_ppm * 10.0f);

	                osMutexRelease(sensorDataMutexHandle);
	            }
	        }

	        osDelay(pdMS_TO_TICKS(2000)); // K33 recommended interval
	    }
  /* USER CODE END StartSensorTask_UART */
}

void StartSensorTask_SPI(void *argument)
{
  /* USER CODE BEGIN StartSensorTask_SPI */
  /* Infinite loop */

	osDelay(pdMS_TO_TICKS(100));

	    EEPROM_Test();

  for(;;)
  {

	  //////////TEST EEPROM//////////////

	          osDelay(pdMS_TO_TICKS(30000));
  }
  /* USER CODE END StartSensorTask_SPI */
}

void StartCommTask_NRF_SD(void *argument)
{
  for(;;)
  {
    osDelay(1);
  }
}
